# Cortex_M4 register map
Vendor: ARM Ltd.; File version: 1.3
CPU: CM4 r0p0, little endian, MPU, no FPU, vendor SysTick, 8 interrupt priority bits
Registers are 32-bit, read-write, no defined reset value unless marked. A register's access mark holds for its fields unless they carry their own. Offsets are from the block's base; [hi:lo] are bit positions; {n}, {i} and the like mark numbered series; 'fields as' and 'values as' point back to an identical list.

## FPE — System Control registers for the FP extension
Base 0xE000EF34
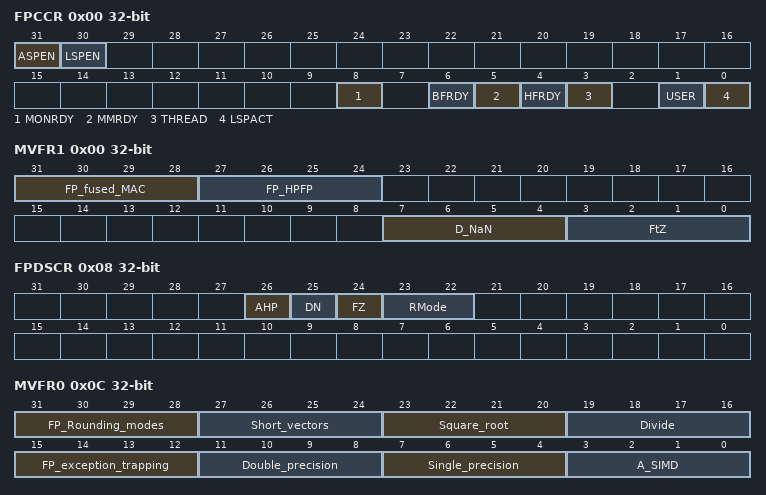
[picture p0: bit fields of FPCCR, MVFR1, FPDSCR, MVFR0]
0x00 FPCCR
  [31] ASPEN
  [30] LSPEN
    0=Disable; 1=Enable
  [8] MONRDY
    0=Not_Able; 1=Able
  [6] BFRDY
    0=Not_Able; 1=Able
  [5] MMRDY
    0=Not_Able; 1=Able
  [4] HFRDY
    0=Not_Able; 1=Able
  [3] THREAD
    0=Handler; 1=Thread
  [1] USER
    0=Privileged; 1=Unprivileged
  [0] LSPACT
    0=Not_Active; 1=Active
0x00 MVFR1 ro
  [all] fields
    1=Supported
  [31:28] FP_fused_MAC
  [27:24] FP_HPFP
  [7:4] D_NaN
  [3:0] FtZ
0x04 FPCAR
0x08 FPDSCR
  [26] AHP, [25] DN, [24] FZ, [23:22] RMode
0x0C MVFR0 ro
  [31:28] FP_Rounding_modes
    1=Supported
  [27:24] Short_vectors
    0=Not_Supported
  [23:20] Square_root
    1=Supported
  [19:16] Divide
    1=Supported
  [15:12] FP_exception_trapping
    0=Not_Supported
  [11:8] Double_precision
    0=Not_Supported
  [7:4] Single_precision
    2=Supported
  [3:0] A_SIMD
    1=_16x64

## ID — ID registers
Base 0xE000ED00
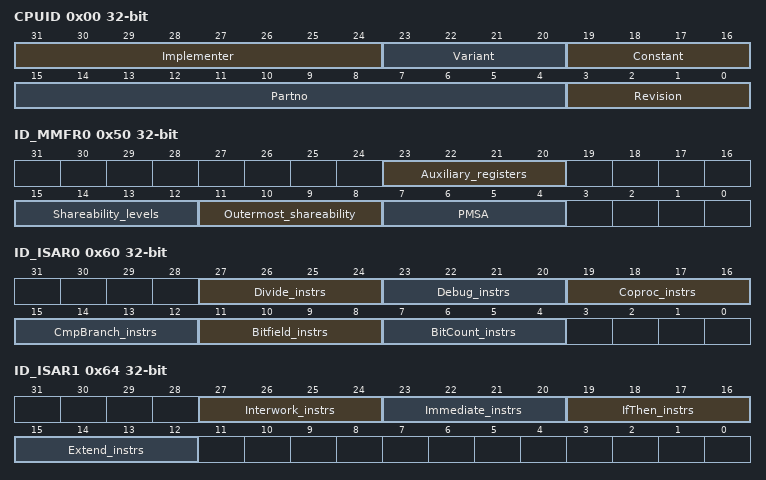
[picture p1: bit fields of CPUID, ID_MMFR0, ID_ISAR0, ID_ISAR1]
0x00 CPUID ro
  [31:24] Implementer, [23:20] Variant, [19:16] Constant, [15:4] Partno, [3:0] Revision
0x40 ID_PFR0 ro
  [7:4] State1
    3=Thumb_Thumb2
0x44 ID_PFR1 ro
  [11:8] M_Profile
    2=Two_stack
0x48 ID_DFR0 ro
  [23:20] M_Profile
    0=Not_supported; 1=Supported
0x4C ID_AFR0 ro
0x50 ID_MMFR0 ro
  [23:20] Auxiliary_registers
    0=Not_supported; 1=Supported
  [15:12] Shareability_levels
    0=One_level
  [11:8] Outermost_shareability
    0=Non_cacheable; 15=Ignored
  [7:4] PMSA
    0=Not_supported; 3=PMSAv7
0x54 ID_MMFR1 ro
0x58 ID_MMFR2 ro
  [27:24] WFI
    0=Not_supported; 1=Supported
0x5C ID_MMFR3 ro
0x60 ID_ISAR0 ro
  [27:24] Divide_instrs
    0=Not_supported; 1=Supported
  [23:20] Debug_instrs
    0=Not_supported; 1=Supported
  [19:16] Coproc_instrs
    0=None; 1=Generic; 2=Generic2; 3=MCRR_MRRC; 4=MCRR2_MRRC2
  [15:12] CmpBranch_instrs
    0=Not_supported; 1=Supported
  [11:8] Bitfield_instrs
    0=Not_supported; 1=Supported
  [7:4] BitCount_instrs
    0=Not_supported; 1=Supported
0x64 ID_ISAR1 ro
  [27:24] Interwork_instrs
    0=None; 1=BX; 2=BX_BLX2
  [23:20] Immediate_instrs
    0=Not_supported; 1=Supported
  [19:16] IfThen_instrs
    0=Not_supported; 1=Supported
  [15:12] Extend_instrs
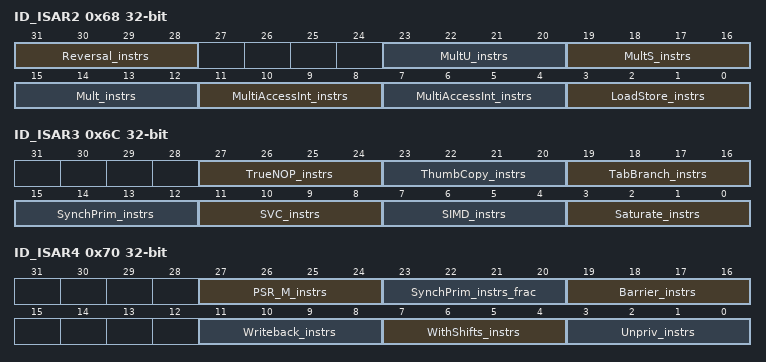
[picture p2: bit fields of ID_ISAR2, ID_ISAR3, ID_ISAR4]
0x68 ID_ISAR2 ro
  [31:28] Reversal_instrs, [23:20] MultU_instrs, [19:16] MultS_instrs, [15:12] Mult_instrs, [11:8] MultiAccessInt_instrs, [7:4] MultiAccessInt_instrs, [3:0] LoadStore_instrs
0x6C ID_ISAR3 ro
  [27:24] TrueNOP_instrs
    0=Not_supported; 1=Supported
  [23:20] ThumbCopy_instrs
    0=Not_supported; 1=Supported
  [19:16] TabBranch_instrs
    0=Not_supported; 1=Supported
  [15:12] SynchPrim_instrs
  [11:8] SVC_instrs
    0=Not_supported; 1=Supported
  [7:4] SIMD_instrs
  [3:0] Saturate_instrs
    0=Not_supported; 1=Supported
0x70 ID_ISAR4 ro
  [27:24] PSR_M_instrs
    0=Not_supported; 1=Supported
  [23:20] SynchPrim_instrs_frac
  [19:16] Barrier_instrs
    0=Not_supported; 1=Supported
  [11:8] Writeback_instrs
    0=Basic; 1=Full
  [7:4] WithShifts_instrs
  [3:0] Unpriv_instrs

## MPU — Memory Protection Unit
Base 0xE000ED90
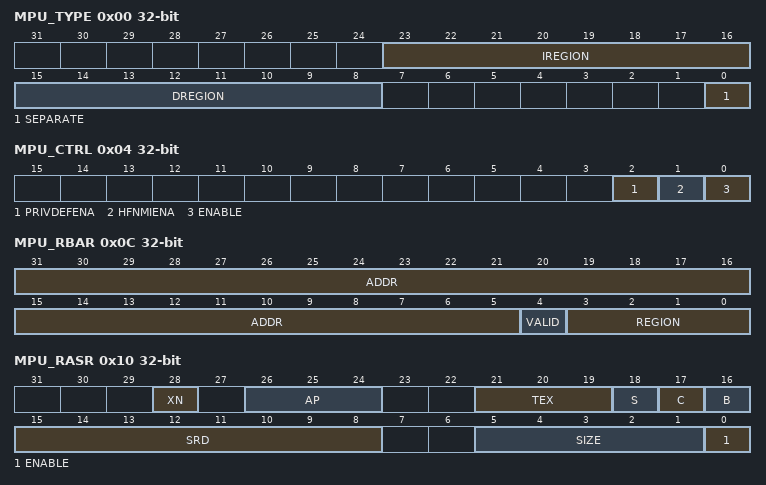
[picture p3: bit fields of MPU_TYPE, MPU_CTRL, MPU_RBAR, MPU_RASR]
0x00 MPU_TYPE ro
  [23:16] IREGION
  [15:8] DREGION
  [0] SEPARATE
    0=Uniform; 1=Separate
0x04 MPU_CTRL — MPU Control Register
  [all] fields
    0=Disabled; 1=Enabled
  [2] PRIVDEFENA
  [1] HFNMIENA
  [0] ENABLE
0x08 MPU_RNR — MPU Region Number Register
  [7:0] REGION
0x0C MPU_RBAR — MPU Region Base Address Register
  [31:5] ADDR
  [4] VALID
    0=Not_valid; 1=Valid
  [3:0] REGION
0x10 MPU_RASR — MPU Region Attribute and Size Register
  [28] XN
    0=Execution_Permitted; 1=Execution_Not_Permitted
  [26:24] AP
    0=Any_access_generates_a_permission_fault; 1=Privileged_access_only; 2=Any_unprivileged_write_generates_a_permission_fault; 3=Full_access; 5=Privileged_read_only; 6=Privileged_and_unprivileged_read_only; 7=Privileged_and_unprivileged_read_only
  [21:19] TEX
  [18] S
  [17] C
  [16] B
  [15:8] SRD
  [5:1] SIZE
  [0] ENABLE
    0=Disabled; 1=Enabled
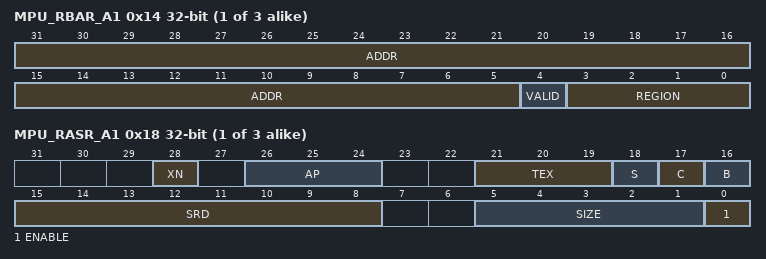
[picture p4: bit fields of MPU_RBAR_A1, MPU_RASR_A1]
{0xC+8i} MPU_RBAR_A{i} (i=1..3) — MPU Alias {i} Region Base Address register
  [31:5] ADDR
  [4] VALID
    0=Not_valid; 1=Valid
  [3:0] REGION
{0x10+8i} MPU_RASR_A{i} (i=1..3) — MPU Alias {i} Region Attribute and Size register
  fields as MPU_RASR

## NVIC — Nested Vectored Interrupt Controller registers
Base 0xE000E100
{0x0+4i} NVIC_ISER{i} reset 0x0 (i=0..7) — Interrupt Set-Enable Register
  [31:0] SETENA
{0x80+4i} NVIC_ICER{i} reset 0x0 (i=0..7) — Interrupt Clear-Enable Register
  [31:0] CLRENA
{0x100+4i} NVIC_ISPR{i} reset 0x0 (i=0..7) — Interrupt Set-Pending Register
  [31:0] SETPEND
{0x180+4i} NVIC_ICPR{i} reset 0x0 (i=0..7) — Interrupt Clear-Pending Register
  [31:0] CLRPEND
{0x200+4i} NVIC_IABR{i} reset 0x0 (i=0..7) — Interrupt Active Bit Register
  [31:0] ACTIVE
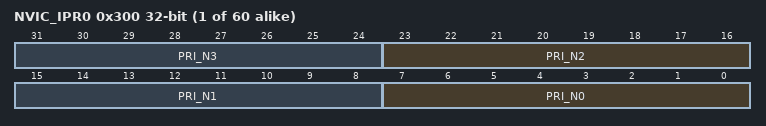
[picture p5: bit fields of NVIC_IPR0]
{0x300+4i} NVIC_IPR{i} (i=0..59)
  [8n+7:8n] PRI_N{n} (n=0..3)

## NVIC_STIR — Nested vectored interrupt controller
Base 0xE000EF00
0x00 STIR wo reset 0x0 — Software trigger interrupt register
  [8:0] INTID — Software generated interrupt ID

## SysTick — System Timer registers
Base 0xE000E010
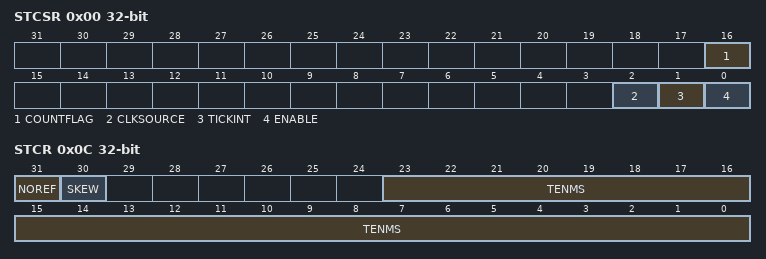
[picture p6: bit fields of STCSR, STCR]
0x00 STCSR
  [16] COUNTFLAG
    0=not_counted_to_0; 1=counted_to_0
  [2] CLKSOURCE
    0=External_clock; 1=Processor_clock
  [1] TICKINT
    0=Does_not_affect_exception_status; 1=Changes_exception_status
  [0] ENABLE
    0=Counter_disabled; 1=Counter_operating
0x04 STRVR
  [23:0] RELOAD
0x08 STCVR
  [23:0] CURRENT
0x0C STCR ro
  [31] NOREF
    0=Implemented; 1=Not_implemented
  [30] SKEW
    0=Exact; 1=Inexact
  [23:0] TENMS
